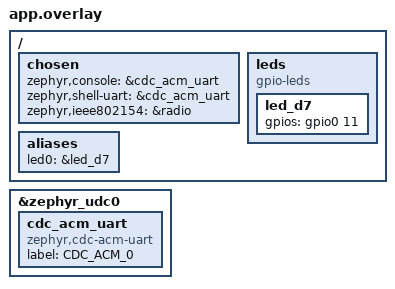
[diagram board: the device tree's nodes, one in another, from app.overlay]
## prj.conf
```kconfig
# =================================================================
# ==           FINAL prj.conf for RAK/Argon End Node           ==
# =================================================================

# --- Basic Application & Kernel Functionality ---
CONFIG_GPIO=y
CONFIG_LOG=y
CONFIG_LOG_DEFAULT_LEVEL=3

# --- Networking Stack ---
CONFIG_NETWORKING=y
CONFIG_NET_UDP=y

# --- OpenThread Stack Configuration ---
CONFIG_NET_L2_OPENTHREAD=y
CONFIG_OPENTHREAD_NORDIC_LIBRARY_MASTER=y
CONFIG_OPENTHREAD_THREAD_VERSION_1_2=y
CONFIG_OPENTHREAD_FTD=y
CONFIG_OPENTHREAD_MTD=n # Must be 'n' for an FTD/Router

# --- Settings Storage for Thread Network Info ---
CONFIG_SETTINGS=y
CONFIG_SETTINGS_FS_DIR="/lfs/settings"
CONFIG_FLASH=y
CONFIG_FLASH_PAGE_LAYOUT=y
CONFIG_LITTLEFS_FS=y
CONFIG_PM_PARTITION_SIZE_SETTINGS_STORAGE=0x8000

# =================================================================
# ==        THE BUILD FIX: Radio and USB Configuration         ==
# =================================================================

# --- Use the standard Zephyr radio driver for the nRF5 radio ---
CONFIG_IEEE802154_NRF5=y
CONFIG_MPSL=y

# --- USB CDC-ACM for Command Line Interface (CLI) ---
CONFIG_USB_DEVICE_STACK=y
CONFIG_USB_DEVICE_PRODUCT="RAK Thread Node"
CONFIG_SHELL=y
CONFIG_OPENTHREAD_SHELL=y
CONFIG_SHELL_BACKEND_SERIAL=y
CONFIG_USB_CDC_ACM=y
CONFIG_UART_LINE_CTRL=y
```

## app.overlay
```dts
/*
 * =================================================================
 * ==           FINAL app.overlay for RAK/Argon End Node          ==
 * =================================================================
 */

/ {
    /* chosen node sets system-wide defaults */
    chosen {
        /* Route the console and shell to the USB virtual COM port */
        zephyr,console = &cdc_acm_uart;
        zephyr,shell-uart = &cdc_acm_uart;

        /* Tell OpenThread which radio device to use. */
        zephyr,ieee802154 = &radio;
    };

    leds {
        compatible = "gpio-leds";
        /* The RAK4631 and Argon both use P0.11 for an accessible LED */
        led_d7: led_d7 {
            gpios = <&gpio0 11 GPIO_ACTIVE_HIGH>;
        };
    };

    aliases {
        /* Create a standard alias "led0" that our C code can use */
        led0 = &led_d7;
    };
};

/* Define the cdc_acm_uart instance on the USB controller */
&zephyr_udc0 {
    cdc_acm_uart: cdc_acm_uart {
        compatible = "zephyr,cdc-acm-uart";
        label = "CDC_ACM_0";
    };
};
```

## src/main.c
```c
/*
 * =================================================================
 * ==      FINAL main.c for End Node (Sending to Border Router)   ==
 * =================================================================
 */
#include <zephyr/kernel.h>
#include <zephyr/device.h>
#include <zephyr/devicetree.h>
#include <zephyr/logging/log.h>
#include <stdio.h>
#include <zephyr/drivers/gpio.h>

#include <zephyr/net/openthread.h>
#include <openthread/udp.h>
#include <openthread/message.h>
#include <openthread/instance.h>
#include <openthread/platform/radio.h>
#include <openthread/thread.h>
#include <openthread/netdata.h> // <-- NEW: Required for finding services

LOG_MODULE_REGISTER(ot_node, CONFIG_LOG_DEFAULT_LEVEL);

// --- Get the LED device spec from the devicetree ---
static const struct gpio_dt_spec led = GPIO_DT_SPEC_GET(DT_ALIAS(led0), gpios);

// --- Port Definitions ---
#define HELLO_PORT 1235
#define NODE_COMMAND_PORT 1236

// --- Global State & Sockets ---
static bool is_reporting = false;
static otUdpSocket command_socket;

// --- Unique ID Function (Unchanged) ---
void get_unique_id_string(char *id_buffer, size_t buffer_size)
{
    otInstance *p_ot_instance = openthread_get_default_instance();
    uint8_t mac_addr[8];
    otPlatRadioGetIeeeEui64(p_ot_instance, mac_addr);
    snprintf(id_buffer, buffer_size, "%02x%02x", mac_addr[6], mac_addr[7]);
}

// --- Hello Message Sender ---
// CHANGED: This function now robustly finds the Border Router's address
void send_hello_to_border_router(void)
{
    otError error = OT_ERROR_NONE;
    otMessage *message;
    otMessageInfo messageInfo;
    otInstance *p_ot_instance = openthread_get_default_instance();
    otUdpSocket udpSocket;

    otNetDataIterator iterator = OT_NET_DATA_ITERATOR_INIT;
    otBorderRouterConfig config;
    bool found_border_router = false;

    // Step 1: Iterate through all the services on the network
    while (otNetDataGetNextOnMeshPrefix(p_ot_instance, &iterator, &config) == OT_ERROR_NONE) {
        // Step 2: Find the service that is marked as the "Default" route
        if (config.mDefaultRoute) {
            // Step 3: We found it! Get the address of the device providing this service.
            // The config.mRloc16 is the short address of the Border Router.
            // We construct the full IPv6 address from the mesh-local prefix and the RLOC.
            const otMeshLocalPrefix *ml_prefix = otThreadGetMeshLocalPrefix(p_ot_instance);
            memcpy(&messageInfo.mPeerAddr.mFields.m8[0], ml_prefix->m8, 8);
            messageInfo.mPeerAddr.mFields.m8[8]  = 0x00;
            messageInfo.mPeerAddr.mFields.m8[9]  = 0x00;
            messageInfo.mPeerAddr.mFields.m8[10] = 0x00;
            messageInfo.mPeerAddr.mFields.m8[11] = 0xff;
            messageInfo.mPeerAddr.mFields.m8[12] = 0xfe;
            messageInfo.mPeerAddr.mFields.m8[13] = 0x00;
            messageInfo.mPeerAddr.mFields.m8[14] = (config.mRloc16 >> 8) & 0xff;
            messageInfo.mPeerAddr.mFields.m8[15] = config.mRloc16 & 0xff;
            
            found_border_router = true;
            break; // Exit the loop since we found what we need
        }
    }

    if (!found_border_router) {
        LOG_WRN("Could not find a default Border Router on the network yet.");
        return;
    }
    
    // Step 4: Send the "hello" message as before
    char unique_id[5];
    char hello_payload[20];
    get_unique_id_string(unique_id, sizeof(unique_id));
    snprintf(hello_payload, sizeof(hello_payload), "hello-%s", unique_id);

    messageInfo.mPeerPort = HELLO_PORT;

    message = otUdpNewMessage(p_ot_instance, NULL);
    if (message) {
        otMessageAppend(message, hello_payload, strlen(hello_payload));
        otUdpOpen(p_ot_instance, &udpSocket, NULL, NULL);
        otUdpSend(p_ot_instance, &udpSocket, message, &messageInfo);
        otUdpClose(p_ot_instance, &udpSocket);
    }
}


// --- Command Listener Callback (with LED logic) ---
void command_receive_callback(void *aContext, otMessage *aMessage, const otMessageInfo *aMessageInfo)
{
    OT_UNUSED_VARIABLE(aContext);
    OT_UNUSED_VARIABLE(aMessageInfo);

    char command_buffer[10];
    int length = otMessageRead(aMessage, otMessageGetOffset(aMessage), command_buffer, sizeof(command_buffer) - 1);
    command_buffer[length] = '\0';

    if (strcmp(command_buffer, "start") == 0) {
        LOG_INF("'start' command received. Beginning to report.");
        is_reporting = true;
        gpio_pin_set_dt(&led, 1); // Turn LED on
    } else if (strcmp(command_buffer, "stop") == 0) {
        LOG_INF("'stop' command received. Halting reports.");
        is_reporting = false;
        gpio_pin_set_dt(&led, 0); // Turn LED off
    }
    otMessageFree(aMessage);
}

// --- Command Listener Setup (Unchanged) ---
void setup_command_listener(void)
{
    otError error;
    otSockAddr sockaddr;
    otInstance *p_ot_instance = openthread_get_default_instance();
    memset(&sockaddr, 0, sizeof(sockaddr));
    sockaddr.mPort = NODE_COMMAND_PORT;
    error = otUdpOpen(p_ot_instance, &command_socket, command_receive_callback, NULL);
    if (error != OT_ERROR_NONE) { LOG_ERR("Failed to open command UDP socket: %d", error); return; }
    error = otUdpBind(p_ot_instance, &command_socket, &sockaddr, OT_NETIF_THREAD);
    if (error != OT_ERROR_NONE) { LOG_ERR("Failed to bind command UDP socket: %d", error); return; }
    LOG_INF("Node command listener started on port %d", NODE_COMMAND_PORT);
}

// --- Main ---
int main(void)
{
    LOG_INF("Starting OpenThread Node Application");

    // Initialize the LED
    if (!device_is_ready(led.port)) { LOG_ERR("LED device not ready"); return -1; }
    if (gpio_pin_configure_dt(&led, GPIO_OUTPUT_INACTIVE) < 0) { LOG_ERR("Failed to configure LED pin"); return -1; }
    LOG_INF("LED initialized.");

    if (openthread_start(openthread_get_default_context()) != 0) {
        LOG_ERR("Failed to start OpenThread");
        return -1;
    }

    setup_command_listener();
    LOG_INF("Node initialized. Waiting for commands.");

    while (1) {
        if (is_reporting && (otThreadGetDeviceRole(openthread_get_default_instance()) > OT_DEVICE_ROLE_DISABLED)) {
            // CHANGED: Call the new function
            send_hello_to_border_router();
        }
        k_sleep(K_SECONDS(1));
    }
    return 0;
}
```
